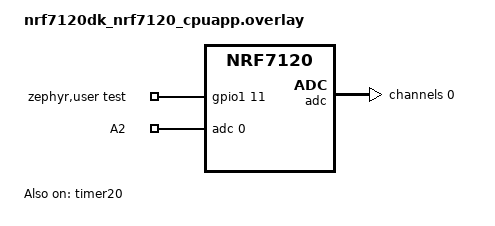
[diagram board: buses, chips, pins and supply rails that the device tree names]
/*
 * Copyright (c) 2026 Nordic Semiconductor ASA
 *
 * SPDX-License-Identifier: LicenseRef-Nordic-5-Clause
 */

/*
 * Required loopbacks:
 * AIN2 <-> VDDIO (Zephyr test loopback set)
 */

/ {
	aliases {
		tst-timer = &timer20;
	};

	zephyr,user {
		test-gpios = <&gpio1 11 GPIO_ACTIVE_HIGH>;
		io-channels = <&adc 0>;
		io-channel-names = "A2";
	};
};

&vbat_monitor {
	status = "disabled";
};

dut_adc: &adc {
	#address-cells = <1>;
	#size-cells = <0>;

	/delete-node/ channel@0;

	channel@0 {
		reg = <0>;
		zephyr,gain = "ADC_GAIN_1";
		zephyr,reference = "ADC_REF_INTERNAL";
		zephyr,acquisition-time = <ADC_ACQ_TIME_DEFAULT>;
		zephyr,input-positive = <NRF_SAADC_AIN1>;
	};
};

&gpio1 {
	status = "okay";
};

&timer20 {
	status = "okay";
};
